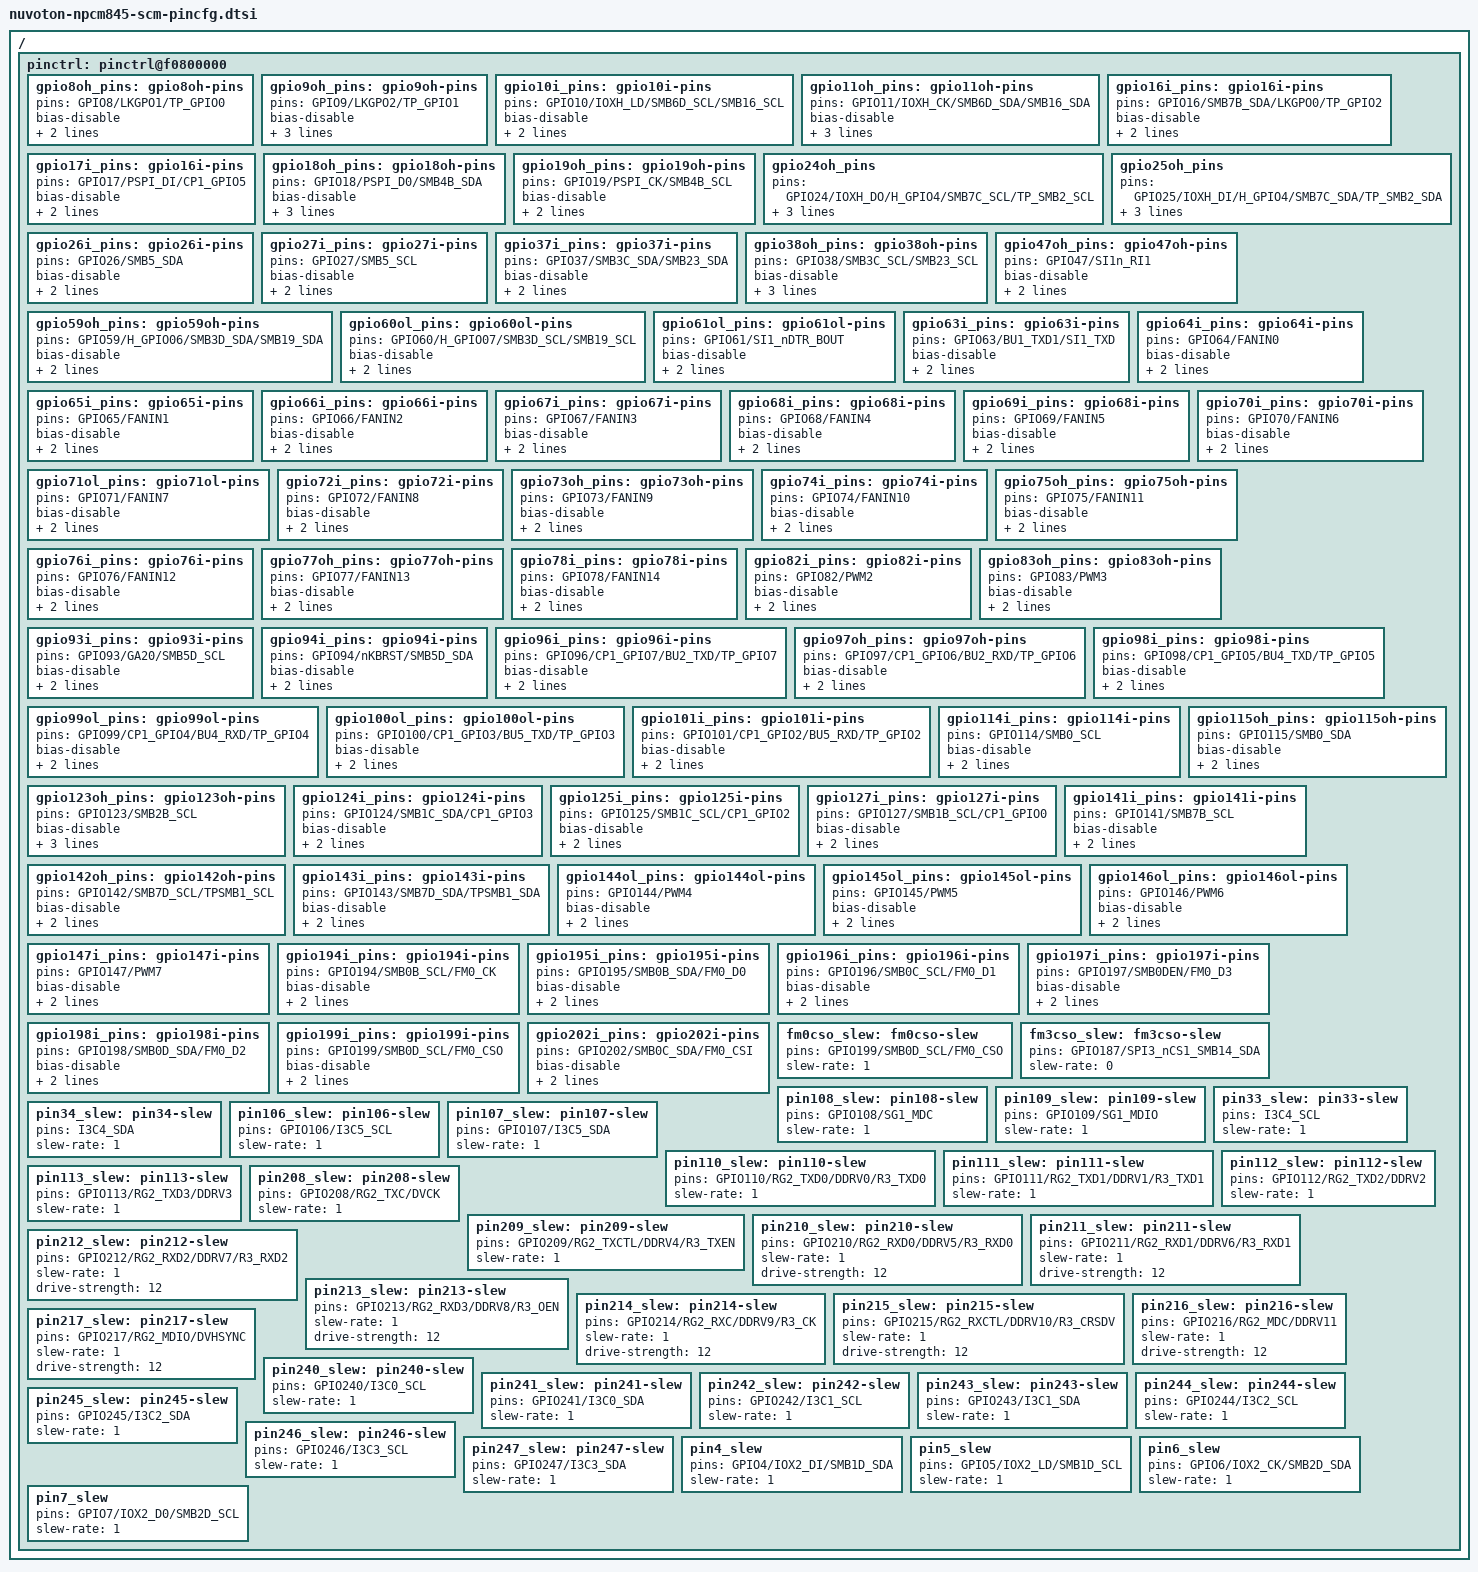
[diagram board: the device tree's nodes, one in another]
// SPDX-License-Identifier: GPL-2.0
// Copyright (c) 2018 Nuvoton Technology

/ {
	pinctrl: pinctrl@f0800000 {
		gpio8oh_pins: gpio8oh-pins {
			pins = "GPIO8/LKGPO1/TP_GPIO0";
			bias-disable;
			output-high;
			persist-enable;
		};
		gpio9oh_pins: gpio9oh-pins {
			pins = "GPIO9/LKGPO2/TP_GPIO1";
			bias-disable;
			output-high;
			drive-open-drain;
			persist-enable;
		};
		gpio10i_pins: gpio10i-pins {
			pins = "GPIO10/IOXH_LD/SMB6D_SCL/SMB16_SCL";
			bias-disable;
			input-enable;
			persist-enable;
		};
		gpio11oh_pins: gpio11oh-pins {
			pins = "GPIO11/IOXH_CK/SMB6D_SDA/SMB16_SDA";
			bias-disable;
			output-high;
			drive-open-drain;
			persist-enable;
		};
		gpio16i_pins: gpio16i-pins {
			pins = "GPIO16/SMB7B_SDA/LKGPO0/TP_GPIO2";
			bias-disable;
			input-enable;
			persist-enable;
		};
		gpio17i_pins: gpio16i-pins {
			pins = "GPIO17/PSPI_DI/CP1_GPIO5";
			bias-disable;
			input-enable;
			persist-enable;
		};
		gpio18oh_pins: gpio18oh-pins {
			pins = "GPIO18/PSPI_D0/SMB4B_SDA";
			bias-disable;
			output-high;
			drive-open-drain;
			persist-enable;
		};
		gpio19oh_pins: gpio19oh-pins {
			pins = "GPIO19/PSPI_CK/SMB4B_SCL";
			bias-disable;
			output-high;
			persist-enable;
		};
		gpio24oh_pins: gpio24oh_pins {
			pins = "GPIO24/IOXH_DO/H_GPIO4/SMB7C_SCL/TP_SMB2_SCL";
			bias-disable;
			output-high;
			persist-enable;
		};
		gpio25oh_pins: gpio25oh_pins {
			pins = "GPIO25/IOXH_DI/H_GPIO4/SMB7C_SDA/TP_SMB2_SDA";
			bias-disable;
			output-high;
			persist-enable;
		};
		gpio26i_pins: gpio26i-pins {
			pins = "GPIO26/SMB5_SDA";
			bias-disable;
			input-enable;
			persist-enable;
		};
		gpio27i_pins: gpio27i-pins {
			pins = "GPIO27/SMB5_SCL";
			bias-disable;
			input-enable;
			persist-enable;
		};
		gpio37i_pins: gpio37i-pins {
			pins = "GPIO37/SMB3C_SDA/SMB23_SDA";
			bias-disable;
			input-enable;
			persist-enable;
		};
		gpio38oh_pins: gpio38oh-pins {
			pins = "GPIO38/SMB3C_SCL/SMB23_SCL";
			bias-disable;
			output-high;
			drive-open-drain;
			persist-enable;
		};
		gpio47oh_pins: gpio47oh-pins {
			pins = "GPIO47/SI1n_RI1";
			bias-disable;
			output-high;
			persist-enable;
		};
		gpio59oh_pins: gpio59oh-pins {
			pins = "GPIO59/H_GPIO06/SMB3D_SDA/SMB19_SDA";
			bias-disable;
			output-high;
			persist-enable;
		};
		gpio60ol_pins: gpio60ol-pins {
			pins = "GPIO60/H_GPIO07/SMB3D_SCL/SMB19_SCL";
			bias-disable;
			output-low;
			persist-enable;
		};
		gpio61ol_pins: gpio61ol-pins {
			pins = "GPIO61/SI1_nDTR_BOUT";
			bias-disable;
			output-low;
			persist-enable;
		};
		gpio63i_pins: gpio63i-pins {
			pins = "GPIO63/BU1_TXD1/SI1_TXD";
			bias-disable;
			input-enable;
			persist-enable;
		};
		gpio64i_pins: gpio64i-pins {
			pins = "GPIO64/FANIN0";
			bias-disable;
			input-enable;
			persist-enable;
		};
		gpio65i_pins: gpio65i-pins {
			pins = "GPIO65/FANIN1";
			bias-disable;
			input-enable;
			persist-enable;
		};
		gpio66i_pins: gpio66i-pins {
			pins = "GPIO66/FANIN2";
			bias-disable;
			input-enable;
			persist-enable;
		};
		gpio67i_pins: gpio67i-pins {
			pins = "GPIO67/FANIN3";
			bias-disable;
			input-enable;
			persist-enable;
		};
		gpio68i_pins: gpio68i-pins {
			pins = "GPIO68/FANIN4";
			bias-disable;
			input-enable;
			persist-enable;
		};
		gpio69i_pins: gpio68i-pins {
			pins = "GPIO69/FANIN5";
			bias-disable;
			input-enable;
			persist-enable;
		};
		gpio70i_pins: gpio70i-pins {
			pins = "GPIO70/FANIN6";
			bias-disable;
			input-enable;
			persist-enable;
		};
		gpio71ol_pins: gpio71ol-pins {
			pins = "GPIO71/FANIN7";
			bias-disable;
			output-low;
			persist-enable;
		};
		gpio72i_pins: gpio72i-pins {
			pins = "GPIO72/FANIN8";
			bias-disable;
			input-enable;
			persist-enable;
		};
		gpio73oh_pins: gpio73oh-pins {
			pins = "GPIO73/FANIN9";
			bias-disable;
			output-high;
			persist-enable;
		};
		gpio74i_pins: gpio74i-pins {
			pins = "GPIO74/FANIN10";
			bias-disable;
			input-enable;
			persist-enable;
		};
		gpio75oh_pins: gpio75oh-pins {
			pins = "GPIO75/FANIN11";
			bias-disable;
			output-high;
			persist-enable;
		};
		gpio76i_pins: gpio76i-pins {
			pins = "GPIO76/FANIN12";
			bias-disable;
			input-enable;
			persist-enable;
		};
		gpio77oh_pins: gpio77oh-pins {
			pins = "GPIO77/FANIN13";
			bias-disable;
			output-high;
			persist-enable;
		};
		gpio78i_pins: gpio78i-pins {
			pins = "GPIO78/FANIN14";
			bias-disable;
			input-enable;
			persist-enable;
		};
		gpio82i_pins: gpio82i-pins {
			pins = "GPIO82/PWM2";
			bias-disable;
			input-enable;
			persist-enable;
		};
		gpio83oh_pins: gpio83oh-pins {
			pins = "GPIO83/PWM3";
			bias-disable;
			output-high;
			persist-enable;
		};
		gpio93i_pins: gpio93i-pins {
			pins = "GPIO93/GA20/SMB5D_SCL";
			bias-disable;
			input-enable;
			persist-enable;
		};
		gpio94i_pins: gpio94i-pins {
			pins = "GPIO94/nKBRST/SMB5D_SDA";
			bias-disable;
			input-enable;
			persist-enable;
		};
		gpio96i_pins: gpio96i-pins {
			pins = "GPIO96/CP1_GPIO7/BU2_TXD/TP_GPIO7";
			bias-disable;
			input-enable;
			persist-enable;
		};
		gpio97oh_pins: gpio97oh-pins {
			pins = "GPIO97/CP1_GPIO6/BU2_RXD/TP_GPIO6";
			bias-disable;
			output-high;
			persist-enable;
		};
		gpio98i_pins: gpio98i-pins {
			pins = "GPIO98/CP1_GPIO5/BU4_TXD/TP_GPIO5";
			bias-disable;
			input-enable;
			persist-enable;
		};
		gpio99ol_pins: gpio99ol-pins {
			pins = "GPIO99/CP1_GPIO4/BU4_RXD/TP_GPIO4";
			bias-disable;
			output-low;
			persist-enable;
		};
		gpio100ol_pins: gpio100ol-pins {
			pins = "GPIO100/CP1_GPIO3/BU5_TXD/TP_GPIO3";
			bias-disable;
			output-low;
			persist-enable;
		};
		gpio101i_pins: gpio101i-pins {
			pins = "GPIO101/CP1_GPIO2/BU5_RXD/TP_GPIO2";
			bias-disable;
			input-enable;
			persist-enable;
		};
		gpio114i_pins: gpio114i-pins {
			pins = "GPIO114/SMB0_SCL";
			bias-disable;
			input-enable;
			persist-enable;
		};
		gpio115oh_pins: gpio115oh-pins {
			pins = "GPIO115/SMB0_SDA";
			bias-disable;
			output-high;
			persist-enable;
		};
		gpio123oh_pins: gpio123oh-pins {
			pins = "GPIO123/SMB2B_SCL";
			bias-disable;
			output-high;
			drive-open-drain;
			persist-enable;
		};
		gpio124i_pins: gpio124i-pins {
			pins = "GPIO124/SMB1C_SDA/CP1_GPIO3";
			bias-disable;
			input-enable;
			persist-enable;
		};
		gpio125i_pins: gpio125i-pins {
			pins = "GPIO125/SMB1C_SCL/CP1_GPIO2";
			bias-disable;
			input-enable;
			persist-enable;
		};
		gpio127i_pins: gpio127i-pins {
			pins = "GPIO127/SMB1B_SCL/CP1_GPIO0";
			bias-disable;
			input-enable;
			persist-enable;
		};
		gpio141i_pins: gpio141i-pins {
			pins = "GPIO141/SMB7B_SCL";
			bias-disable;
			input-enable;
			persist-enable;
		};
		gpio142oh_pins: gpio142oh-pins {
			pins = "GPIO142/SMB7D_SCL/TPSMB1_SCL";
			bias-disable;
			output-high;
			persist-enable;
		};
		gpio143i_pins: gpio143i-pins {
			pins = "GPIO143/SMB7D_SDA/TPSMB1_SDA";
			bias-disable;
			input-enable;
			persist-enable;
		};
		gpio144ol_pins: gpio144ol-pins {
			pins = "GPIO144/PWM4";
			bias-disable;
			output-low;
			persist-enable;
		};
		gpio145ol_pins: gpio145ol-pins {
			pins = "GPIO145/PWM5";
			bias-disable;
			output-low;
			persist-enable;
		};
		gpio146ol_pins: gpio146ol-pins {
			pins = "GPIO146/PWM6";
			bias-disable;
			ouput-low;
			persist-enable;
		};
		gpio147i_pins: gpio147i-pins {
			pins = "GPIO147/PWM7";
			bias-disable;
			input-enable;
			persist-enable;
		};
		gpio194i_pins: gpio194i-pins {
			pins = "GPIO194/SMB0B_SCL/FM0_CK";
			bias-disable;
			input-enable;
			persist-enable;
		};
		gpio195i_pins: gpio195i-pins {
			pins = "GPIO195/SMB0B_SDA/FM0_D0";
			bias-disable;
			input-enable;
			persist-enable;
		};
		gpio196i_pins: gpio196i-pins {
			pins = "GPIO196/SMB0C_SCL/FM0_D1";
			bias-disable;
			input-enable;
			persist-enable;
		};
		gpio197i_pins: gpio197i-pins {
			pins = "GPIO197/SMB0DEN/FM0_D3";
			bias-disable;
			input-enable;
			persist-enable;
		};
		gpio198i_pins: gpio198i-pins {
			pins = "GPIO198/SMB0D_SDA/FM0_D2";
			bias-disable;
			input-enable;
			persist-enable;
		};
		gpio199i_pins: gpio199i-pins {
			pins = "GPIO199/SMB0D_SCL/FM0_CSO";
			bias-disable;
			input-enable;
			persist-enable;
		};
		gpio202i_pins: gpio202i-pins {
			pins = "GPIO202/SMB0C_SDA/FM0_CSI";
			bias-disable;
			input-enable;
			persist-enable;
		};

		fm0cso_slew: fm0cso-slew {
			pins = "GPIO199/SMB0D_SCL/FM0_CSO";
			slew-rate = <1>;
		};
		fm3cso_slew: fm3cso-slew {
			pins = "GPIO187/SPI3_nCS1_SMB14_SDA";
			slew-rate = <0>;
		};
		pin108_slew: pin108-slew {
			pins = "GPIO108/SG1_MDC";
			slew-rate = <1>;
		};
		pin109_slew: pin109-slew {
			pins = "GPIO109/SG1_MDIO";
			slew-rate = <1>;
		};
		pin33_slew: pin33-slew {
			pins = "I3C4_SCL";
			slew-rate = <1>;
		};
		pin34_slew: pin34-slew {
			pins = "I3C4_SDA";
			slew-rate = <1>;
		};
		pin106_slew: pin106-slew {
			pins = "GPIO106/I3C5_SCL";
			slew-rate = <1>;
		};
		pin107_slew: pin107-slew {
			pins = "GPIO107/I3C5_SDA";
			slew-rate = <1>;
		};
		pin110_slew: pin110-slew {
			pins = "GPIO110/RG2_TXD0/DDRV0/R3_TXD0";
			slew-rate = <1>;
		};
		pin111_slew: pin111-slew {
			pins = "GPIO111/RG2_TXD1/DDRV1/R3_TXD1";
			slew-rate = <1>;
		};
		pin112_slew: pin112-slew {
			pins = "GPIO112/RG2_TXD2/DDRV2";
			slew-rate = <1>;
		};
		pin113_slew: pin113-slew {
			pins = "GPIO113/RG2_TXD3/DDRV3";
			slew-rate = <1>;
		};
		pin208_slew: pin208-slew {
			pins = "GPIO208/RG2_TXC/DVCK";
			slew-rate = <1>;
		};
		pin209_slew: pin209-slew {
			pins = "GPIO209/RG2_TXCTL/DDRV4/R3_TXEN";
			slew-rate = <1>;
		};
		pin210_slew: pin210-slew {
			pins = "GPIO210/RG2_RXD0/DDRV5/R3_RXD0";
			slew-rate = <1>;
			drive-strength = <12>;
		};
		pin211_slew: pin211-slew {
			pins = "GPIO211/RG2_RXD1/DDRV6/R3_RXD1";
			slew-rate = <1>;
			drive-strength = <12>;
		};
		pin212_slew: pin212-slew {
			pins = "GPIO212/RG2_RXD2/DDRV7/R3_RXD2";
			slew-rate = <1>;
			drive-strength = <12>;
		};
		pin213_slew: pin213-slew {
			pins = "GPIO213/RG2_RXD3/DDRV8/R3_OEN";
			slew-rate = <1>;
			drive-strength = <12>;
		};
		pin214_slew: pin214-slew {
			pins = "GPIO214/RG2_RXC/DDRV9/R3_CK";
			slew-rate = <1>;
			drive-strength = <12>;
		};
		pin215_slew: pin215-slew {
			pins = "GPIO215/RG2_RXCTL/DDRV10/R3_CRSDV";
			slew-rate = <1>;
			drive-strength = <12>;
		};
		pin216_slew: pin216-slew {
			pins = "GPIO216/RG2_MDC/DDRV11";
			slew-rate = <1>;
			drive-strength = <12>;
		};
		pin217_slew: pin217-slew {
			pins = "GPIO217/RG2_MDIO/DVHSYNC";
			slew-rate = <1>;
			drive-strength = <12>;
		};
		pin240_slew: pin240-slew {
			pins = "GPIO240/I3C0_SCL";
			slew-rate = <1>;
		};
		pin241_slew: pin241-slew {
			pins = "GPIO241/I3C0_SDA";
			slew-rate = <1>;
		};
		pin242_slew: pin242-slew {
			pins = "GPIO242/I3C1_SCL";
			slew-rate = <1>;
		};
		pin243_slew: pin243-slew {
			pins = "GPIO243/I3C1_SDA";
			slew-rate = <1>;
		};
		pin244_slew: pin244-slew {
			pins = "GPIO244/I3C2_SCL";
			slew-rate = <1>;
		};
		pin245_slew: pin245-slew {
			pins = "GPIO245/I3C2_SDA";
			slew-rate = <1>;
		};
		pin246_slew: pin246-slew {
			pins = "GPIO246/I3C3_SCL";
			slew-rate = <1>;
		};
		pin247_slew: pin247-slew {
			pins = "GPIO247/I3C3_SDA";
			slew-rate = <1>;
		};
		pin4_slew: pin4_slew {
			pins = "GPIO4/IOX2_DI/SMB1D_SDA";
			slew-rate = <1>;
		};
		pin5_slew: pin5_slew {
			pins = "GPIO5/IOX2_LD/SMB1D_SCL";
			slew-rate = <1>;
		};
		pin6_slew: pin6_slew {
			pins = "GPIO6/IOX2_CK/SMB2D_SDA";
			slew-rate = <1>;
		};
		pin7_slew: pin7_slew {
			pins = "GPIO7/IOX2_D0/SMB2D_SCL";
			slew-rate = <1>;
		};
	};
};
